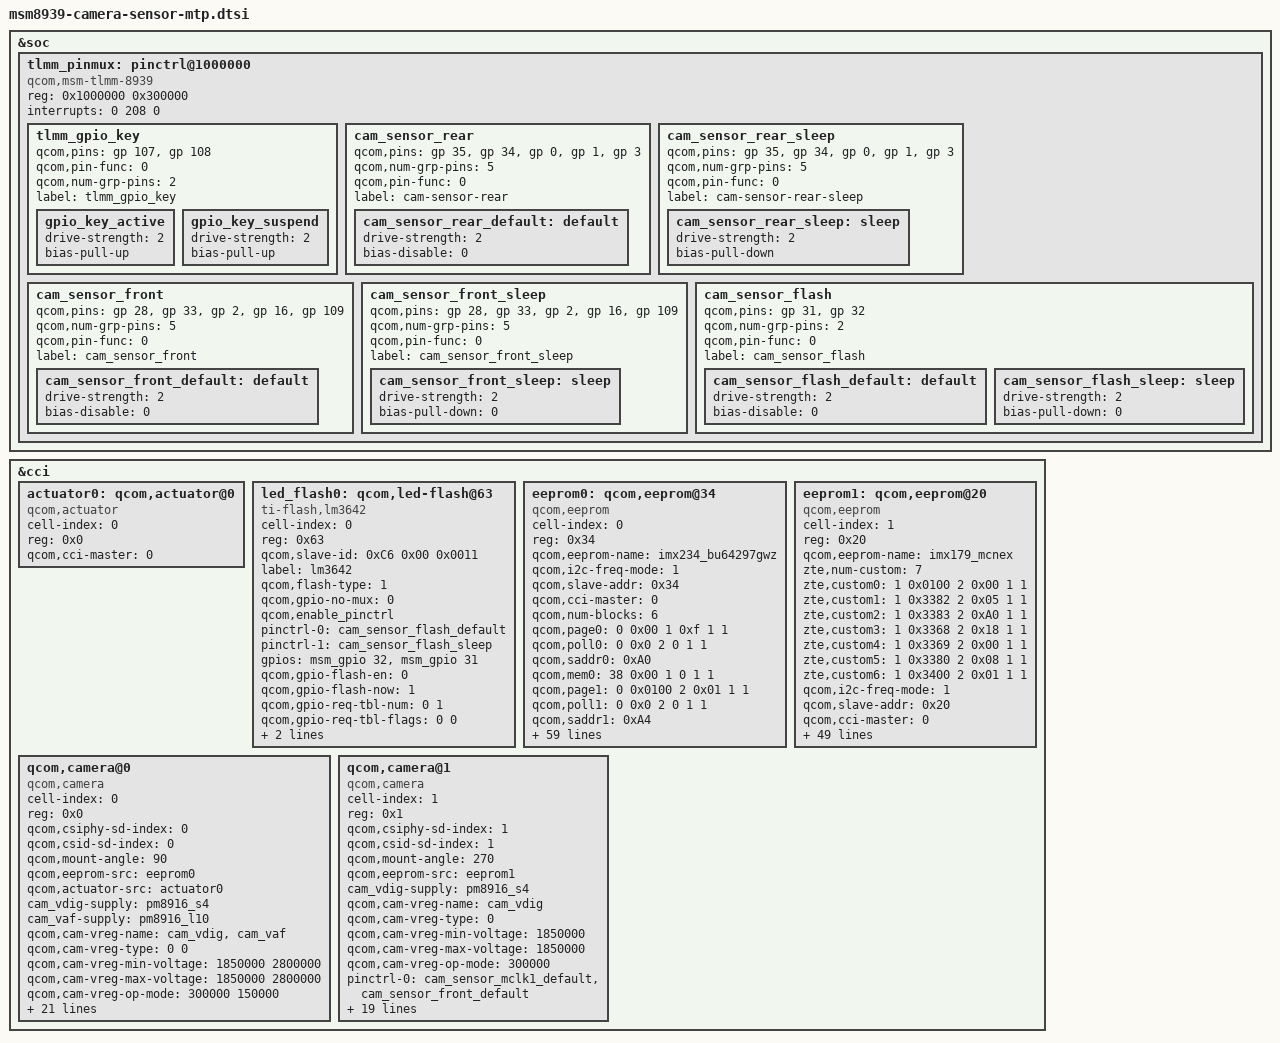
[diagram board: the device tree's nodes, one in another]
/*
 * Copyright (c) 2014, The Linux Foundation. All rights reserved.
 *
 * This program is free software; you can redistribute it and/or modify
 * it under the terms of the GNU General Public License version 2 and
 * only version 2 as published by the Free Software Foundation.
 *
 * This program is distributed in the hope that it will be useful,
 * but WITHOUT ANY WARRANTY; without even the implied warranty of
 * MERCHANTABILITY or FITNESS FOR A PARTICULAR PURPOSE.  See the
 * GNU General Public License for more details.
 */

&soc {
	tlmm_pinmux: pinctrl@1000000 {
		compatible = "qcom,msm-tlmm-8939", "qcom,msm-tlmm-8916";
		reg = <0x1000000 0x300000>;
		interrupts = <0 208 0>;
		tlmm_gpio_key {
			qcom,pins = <&gp 107>, <&gp 108>;/* get rid of 109 by congshan*/
			qcom,pin-func = <0>;
			qcom,num-grp-pins = <2>;
			label = "tlmm_gpio_key";
			gpio_key_active: gpio_key_active {
				drive-strength = <2>;
				bias-pull-up;
			};
			gpio_key_suspend: gpio_key_suspend {
				drive-strength = <2>;
				bias-pull-up;
			};
		};
		cam_sensor_rear {
			/* RESET, STANDBY */
			qcom,pins =  <&gp 35>, <&gp 34>, <&gp 0>, <&gp 1>, <&gp 3>; /*add gp 0 1 3 by congshan */
			qcom,num-grp-pins = <5>;
			qcom,pin-func = <0>;
			label = "cam-sensor-rear";
			/* active state */
			cam_sensor_rear_default: default {
				drive-strength = <2>; /* 2 MA */
				bias-disable = <0>; /* No PULL */
			};
		};

		cam_sensor_rear_sleep {
			/* RESET, STANDBY */
			qcom,pins =  <&gp 35>, <&gp 34>, <&gp 0>, <&gp 1>, <&gp 3>; /*add gp 0 1 3 by congshan */
			qcom,num-grp-pins = <5>;
			qcom,pin-func = <0>;
			label = "cam-sensor-rear-sleep";
			/*suspend state */
			cam_sensor_rear_sleep: sleep {
				drive-strength = <2>; /* 2 MA */
				bias-pull-down; /* PULL DOWN */
			};
		};

		cam_sensor_front {
			/* RESET, STANDBY */
			qcom,pins = <&gp 28>, <&gp 33>, <&gp 2>, <&gp 16>, <&gp 109>; /*add gp 2 16 109 by congshan */
			qcom,num-grp-pins = <5>;
			qcom,pin-func = <0>;
			label = "cam_sensor_front";
			/* active state */
			cam_sensor_front_default: default {
				drive-strength = <2>; /* 2 MA */
				bias-disable = <0>; /* No PULL */
			};
		};

		cam_sensor_front_sleep {
			/* RESET, STANDBY */
			qcom,pins = <&gp 28>, <&gp 33>, <&gp 2>, <&gp 16>, <&gp 109>; /*add gp 2 16 109 by congshan */
			qcom,num-grp-pins = <5>;
			qcom,pin-func = <0>;
			label = "cam_sensor_front_sleep";
			/*suspend state */
			cam_sensor_front_sleep: sleep {
				drive-strength = <2>; /* 2 MA */
				bias-pull-down = <0>; /* PULL DOWN */
			};
		};

		cam_sensor_flash {
			/* FLSH_RESET,FLASH_EN,FLASH_NOW */
			qcom,pins =  <&gp 31>,<&gp 32> ;//change by congshan
			qcom,num-grp-pins = <2>;
			qcom,pin-func = <0>;
			label = "cam_sensor_flash";
			/* active state */
			cam_sensor_flash_default: default {
				drive-strength = <2>; /* 2 MA */
				bias-disable = <0>; /* No PULL */
			};
			/*suspended state */
			cam_sensor_flash_sleep: sleep {
				drive-strength = <2>; /* 2 MA */
				bias-pull-down = <0>; /* PULL DOWN */
			};
		};
	};
};


&cci {

	actuator0: qcom,actuator@0 {
		cell-index = <0>;
		reg = <0x0>;
		compatible = "qcom,actuator";
		qcom,cci-master = <0>;
		/*cam_vaf-supply = <&pm8916_l10>;
		qcom,cam-vreg-name = "cam_vaf";
		qcom,cam-vreg-min-voltage = <2800000>;
		qcom,cam-vreg-max-voltage = <2800000>;
		qcom,cam-vreg-op-mode = <80000>;*/
	};
	led_flash0: qcom,led-flash@63 {
		cell-index = <0>;
		reg = <0x63>;
		qcom,slave-id = <0xC6 0x00 0x0011>;
		compatible = "ti-flash,lm3642";
		label = "lm3642";
		qcom,flash-type = <1>;
		qcom,gpio-no-mux = <0>;
		qcom,enable_pinctrl;
		pinctrl-names = "cam_flash_default", "cam_flash_suspend";
		pinctrl-0 = <&cam_sensor_flash_default>;
		pinctrl-1 = <&cam_sensor_flash_sleep>;
		gpios = <&msm_gpio 32 0>,
			<&msm_gpio 31 0>;
		qcom,gpio-flash-en = <0>;
		qcom,gpio-flash-now = <1>;
		qcom,gpio-req-tbl-num = <0 1>;
		qcom,gpio-req-tbl-flags = <0 0>;
		qcom,gpio-req-tbl-label = "FLASH_EN",
			"FLASH_NOW";
		qcom,cci-master = <0>;
	};
	eeprom0: qcom,eeprom@34 {
		cell-index = <0>;
		reg = <0x34>;
		qcom,eeprom-name = "imx234_bu64297gwz";
		compatible = "qcom,eeprom";
		qcom,i2c-freq-mode = <1>;
		qcom,slave-addr = <0x34>;
		qcom,cci-master = <0>;
		qcom,num-blocks = <6>;
		qcom,page0 = <0 0x00 1 0xf 1 1>;
		qcom,poll0 = <0 0x0 2 0 1 1>;
		qcom,saddr0 =<0xA0>;
		qcom,mem0 = <38 0x00 1 0 1 1>;
		qcom,page1 = <0 0x0100 2 0x01 1 1>;
		qcom,poll1 = <0 0x0 2 0 1 1>;
		qcom,saddr1 =<0xA4>;
		qcom,mem1 = <256 0x00 1 0 1 0>;
		qcom,page2 = <0 0x0100 2 0x01 1 1>;
		qcom,poll2 = <0 0x0 2 0 1 1>;
		qcom,saddr2 =<0xA6>;
		qcom,mem2 = <256 0x00 1 0 1 0>;
		qcom,page3 = <0 0x0100 2 0x01 1 1>;
		qcom,poll3 = <0 0x0 2 0 1 1>;
		qcom,saddr3 =<0xA8>;
		qcom,mem3 = <256 0x00 1 0 1 0>;
		qcom,page4 = <0 0x0100 2 0x01 1 1>;
		qcom,poll4 = <0 0x0 2 0 1 1>;
		qcom,saddr4 =<0xAA>;
		qcom,mem4 = <256 0x00 1 0 1 0>;
		qcom,page5 = <0 0x0100 2 0x01 1 1>;
		qcom,poll5 = <0 0x0 2 0 1 1>;
		qcom,saddr5 =<0xAC>;
		qcom,mem5 = <85 0x00 1 0 1 0>;
		cam_vdig-supply = <&pm8916_s4>;
		cam_vaf-supply = <&pm8916_l10>;
		qcom,cam-vreg-name = "cam_vdig", "cam_vaf";
		qcom,cam-vreg-type = <0 0>;
		qcom,cam-vreg-min-voltage = <1850000 2800000>;
		qcom,cam-vreg-max-voltage = <1850000 2800000>;
		qcom,cam-vreg-op-mode = <300000 150000>;
		pinctrl-names = "cam_default", "cam_suspend";
		pinctrl-0 = <&cam_sensor_mclk0_default &cam_sensor_rear_default>;
		pinctrl-1 = <&cam_sensor_mclk0_sleep &cam_sensor_rear_sleep>;
		gpios = <&msm_gpio 26 0>,
			<&msm_gpio 35 0>,
			<&msm_gpio 34 0>,
			<&msm_gpio 1 0>,
			<&msm_gpio 3 0>,
			<&msm_gpio 0 0>;
		qcom,gpio-reset = <1>;
		qcom,gpio-standby = <2>;
		qcom,gpio-vdig = <3>;
		qcom,gpio-vana = <4>;
		qcom,gpio-vio = <5>;
		qcom,gpio-req-tbl-num = <0 1 2 3 4 5>;
		qcom,gpio-req-tbl-flags = <1 0 0 0 0 0>;
		qcom,gpio-req-tbl-label = "CAMIF_MCLK0",
			"CAM_RESET0",
			"CAM_STANDBY0",
			"CAM_VDIG0",
			"CAM_VANA0",
			"CAM_VIO0";
		qcom,cam-power-seq-type = "sensor_vreg", "sensor_vreg", "sensor_gpio", 
				"sensor_gpio", "sensor_gpio", "sensor_gpio",
				"sensor_gpio", "sensor_gpio", "sensor_gpio",
				"sensor_gpio", "sensor_gpio", "sensor_gpio", 
		        "sensor_clk", "sensor_i2c_mux";
		qcom,cam-power-seq-val = "cam_vdig", "cam_vaf", "sensor_gpio_vdig", 
				"sensor_gpio_vdig", "sensor_gpio_vio", "sensor_gpio_vio", 
				"sensor_gpio_vana", "sensor_gpio_vana", "sensor_gpio_reset",
		        "sensor_gpio_reset",
		        "sensor_gpio_standby",
		        "sensor_gpio_standby",
		        "sensor_cam_mclk",
		        "none";
		qcom,cam-power-seq-cfg-val = <1 1 0 1 0 1 0 1 0 1 0 1 24000000 0>;
		qcom,cam-power-seq-delay =   <1 1 1 1 1 1 1 1 1 30 1 30 1 0>;
		status = "ok";
		clocks = <&clock_gcc clk_mclk0_clk_src>,
				<&clock_gcc clk_gcc_camss_mclk0_clk>;
		clock-names = "cam_src_clk", "cam_clk";
	};
	eeprom1: qcom,eeprom@20 {
		cell-index = <1>;
		reg = <0x20>;
		qcom,eeprom-name = "imx179_mcnex";
		compatible = "qcom,eeprom";
		zte,num-custom = <7>;
		zte,custom0 = <1 0x0100 2 0x00 1 1>;
		zte,custom1 = <1 0x3382 2 0x05 1 1>;
		zte,custom2 = <1 0x3383 2 0xA0 1 1>;
		zte,custom3 = <1 0x3368 2 0x18 1 1>;
		zte,custom4 = <1 0x3369 2 0x00 1 1>;
		zte,custom5 = <1 0x3380 2 0x08 1 1>;
		zte,custom6 = <1 0x3400 2 0x01 1 1>;
		qcom,i2c-freq-mode = <1>;
		qcom,slave-addr = <0x20>;
		qcom,cci-master = <0>;
		qcom,num-blocks = <2>;
		qcom,page0 = <1 0x3402 2 0x00 1 1>;
		qcom,poll0 = <0 0x0 2 0 1 1>;
		qcom,saddr0 =<0x20>;
		qcom,mem0 = <64 0x3404 2 0 1 1>;
		qcom,page1 = <1 0x3402 2 0x01 1 1>;
		qcom,poll1 = <0 0x0 2 0 1 1>;
		qcom,saddr1 =<0x20>;
		qcom,mem1 = <64 0x3404 2 0 1 1>;
				
		cam_vdig-supply = <&pm8916_s4>;
		qcom,cam-vreg-name = "cam_vdig";
		qcom,cam-vreg-type = <0>;
		qcom,cam-vreg-min-voltage = <1850000>;
		qcom,cam-vreg-max-voltage = <1850000>;
		qcom,cam-vreg-op-mode = <300000>;
		pinctrl-names = "cam_default", "cam_suspend";
		pinctrl-0 = <&cam_sensor_mclk1_default &cam_sensor_front_default>;
		pinctrl-1 = <&cam_sensor_mclk1_sleep &cam_sensor_front_sleep>;
		gpios = <&msm_gpio 27 0>,
			<&msm_gpio 28 0>,
			<&msm_gpio 33 0>,
			<&msm_gpio 109 0>,
			<&msm_gpio 2  0>,
			<&msm_gpio 16 0>;
		qcom,gpio-reset = <1>;
		qcom,gpio-standby = <2>;
		qcom,gpio-vdig = <3>;
		qcom,gpio-vana = <4>;
		qcom,gpio-vio = <5>;
		qcom,gpio-req-tbl-num = <0 1 2 3 4 5>;
		qcom,gpio-req-tbl-flags = <1 0 0 0 0 0>;
		qcom,gpio-req-tbl-label = "CAMIF_MCLK1",
			"CAM_RESET1",
			"CAM_STANDBY1",
			"CAM_VDIG1",
			"CAM_VANA1",
			"CAM_VIO1";
		qcom,cam-power-seq-type = "sensor_vreg", "sensor_gpio", 
				"sensor_gpio", "sensor_gpio", "sensor_gpio",
				"sensor_gpio", "sensor_gpio", "sensor_gpio",
				"sensor_gpio", "sensor_gpio", "sensor_gpio", 
		        "sensor_clk", "sensor_i2c_mux";
		qcom,cam-power-seq-val = "cam_vdig", "sensor_gpio_vdig", 
				"sensor_gpio_vdig", "sensor_gpio_vana", "sensor_gpio_vana", 
				"sensor_gpio_vio", "sensor_gpio_vio","sensor_gpio_reset",
		        "sensor_gpio_reset",
		        "sensor_gpio_standby",
		        "sensor_gpio_standby",
		        "sensor_cam_mclk",
		        "none";
		qcom,cam-power-seq-cfg-val = <1 0 1 0 1 0 1 0 1 0 1 24000000 0>;
		qcom,cam-power-seq-delay =   <1 1 1 1 1 1 1 1 30 1 30 1 0>;
		status = "ok";
		clocks = <&clock_gcc clk_mclk1_clk_src>,
				<&clock_gcc clk_gcc_camss_mclk1_clk>;
		clock-names = "cam_src_clk", "cam_clk";
	};
	qcom,camera@0 {
		cell-index = <0>;
		compatible = "qcom,camera";
		reg = <0x0>;
		qcom,csiphy-sd-index = <0>;
		qcom,csid-sd-index = <0>;
		qcom,mount-angle = <90>;
		qcom,eeprom-src = <&eeprom0>;
		qcom,actuator-src = <&actuator0>;
		cam_vdig-supply = <&pm8916_s4>;
		cam_vaf-supply = <&pm8916_l10>;
		qcom,cam-vreg-name = "cam_vdig", "cam_vaf";
		qcom,cam-vreg-type = <0 0>;
		qcom,cam-vreg-min-voltage = <1850000 2800000>;
		qcom,cam-vreg-max-voltage = <1850000 2800000>;
		qcom,cam-vreg-op-mode = <300000 150000>;
		pinctrl-names = "cam_default", "cam_suspend";
		pinctrl-0 = <&cam_sensor_mclk0_default
				&cam_sensor_rear_default>;
		pinctrl-1 = <&cam_sensor_mclk0_sleep &cam_sensor_rear_sleep>;
		gpios = <&msm_gpio 26 0>,
			<&msm_gpio 35 0>,
			<&msm_gpio 34 0>,
			<&msm_gpio 1 0>,
			<&msm_gpio 3 0>,
			<&msm_gpio 0 0>;
		qcom,gpio-reset = <1>;
		qcom,gpio-standby = <2>;
		qcom,gpio-vdig = <3>;
		qcom,gpio-vana = <4>;
		qcom,gpio-vio = <5>;
		qcom,gpio-req-tbl-num = <0 1 2 3 4 5>;
		qcom,gpio-req-tbl-flags = <1 0 0 0 0 0>;
		qcom,gpio-req-tbl-label = "CAMIF_MCLK0",
			"CAM_RESET0",
			"CAM_STANDBY0",
			"CAM_VDIG0",
			"CAM_VANA0",
			"CAM_VIO0";
		qcom,sensor-position = <0>;
		qcom,sensor-mode = <0>;
		qcom,cci-master = <0>;
		status = "ok";
		clocks = <&clock_gcc clk_mclk0_clk_src>,
				<&clock_gcc clk_gcc_camss_mclk0_clk>;
		clock-names = "cam_src_clk", "cam_clk";
	};

	qcom,camera@1 {
		cell-index = <1>;
		compatible = "qcom,camera";
		reg = <0x1>;
		qcom,csiphy-sd-index = <1>;
		qcom,csid-sd-index = <1>;
		qcom,mount-angle = <270>;
		qcom,eeprom-src = <&eeprom1>;
		cam_vdig-supply = <&pm8916_s4>;
		qcom,cam-vreg-name = "cam_vdig";
		qcom,cam-vreg-type = <0>;
		qcom,cam-vreg-min-voltage = <1850000>;
		qcom,cam-vreg-max-voltage = <1850000>;
		qcom,cam-vreg-op-mode = <300000>;
		pinctrl-names = "cam_default", "cam_suspend";
		pinctrl-0 = <&cam_sensor_mclk1_default &cam_sensor_front_default>;
		pinctrl-1 = <&cam_sensor_mclk1_sleep &cam_sensor_front_sleep>;
		gpios = <&msm_gpio 27 0>,
			<&msm_gpio 28 0>,
			<&msm_gpio 33 0>,
			<&msm_gpio 109 0>,
			<&msm_gpio 2  0>,
			<&msm_gpio 16 0>;
		qcom,gpio-reset = <1>;
		qcom,gpio-standby = <2>;
		qcom,gpio-vdig = <3>;
		qcom,gpio-vana = <4>;
		qcom,gpio-vio = <5>;
		qcom,gpio-req-tbl-num = <0 1 2 3 4 5>;
		qcom,gpio-req-tbl-flags = <1 0 0 0 0 0>;
		qcom,gpio-req-tbl-label = "CAMIF_MCLK1",
			"CAM_RESET1",
			"CAM_STANDBY1",
			"CAM_VDIG1",
			"CAM_VANA1",
			"CAM_VIO1";
		qcom,sensor-position = <1>;
		qcom,sensor-mode = <0>;
		qcom,cci-master = <0>;
		status = "ok";
		clocks = <&clock_gcc clk_mclk1_clk_src>,
				<&clock_gcc clk_gcc_camss_mclk1_clk>;
		clock-names = "cam_src_clk", "cam_clk";
	};
};
